# AT90PWM1 device description
Architecture: AVR8; Family: megaAVR
Registers are 8-bit, access not given, no defined reset value unless marked. A register's access mark holds for its fields unless they carry their own. Offsets are from the block's base; [hi:lo] are bit positions; {n}, {i} and the like mark numbered series; 'fields as' and 'values as' point back to an identical list.

## PSC2 — Power Stage Controller
Instances: PSC2 0x00
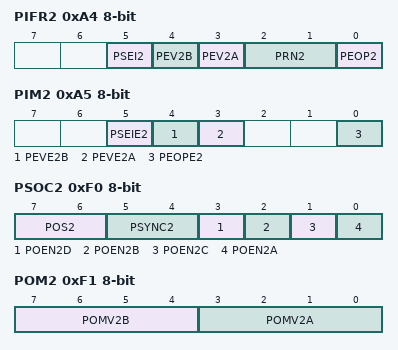
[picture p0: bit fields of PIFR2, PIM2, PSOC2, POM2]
0xA4 PIFR2 — PSC2 Interrupt Flag Register
  [5] PSEI2 — PSC 2 Synchro Error Interrupt
  [4] PEV2B — External Event B Interrupt
  [3] PEV2A — External Event A Interrupt
  [2:1] PRN2 — Ramp Number
    {v}={v+1} (v=0..3)
  [0] PEOP2 — End of PSC2 Interrupt
0xA5 PIM2 — PSC2 Interrupt Mask Register
  [5] PSEIE2 — PSC 2 Synchro Error Interrupt Enable
  [4] PEVE2B — External Event B Interrupt Enable
  [3] PEVE2A — External Event A Interrupt Enable
  [0] PEOPE2 — End of Cycle Interrupt Enable
0xF0 PSOC2 — PSC2 Synchro and Output Configuration
  [7:6] POS2 (bit 2 of the value upward) — PSC 2 Output 23 Select
  [5:4] PSYNC2 — Synchronization Out for ADC Selection
  [3] POEN2D — PSCOUT23 Output Enable
  [2] POEN2B — PSCOUT21 Output Enable
  [1] POEN2C — PSCOUT22 Output Enable
  [0] POEN2A — PSCOUT20 Output Enable
0xF1 POM2 — PSC 2 Output Matrix
  [7:4] POMV2B — Output Matrix Output B Ramps
  [3:0] POMV2A — Output Matrix Output A Ramps
0xF2 OCR2SA 16-bit bits used 11:0 — Output Compare SA Register
0xF4 OCR2RA 16-bit bits used 11:0 — Output Compare RA Register
0xF6 OCR2SB 16-bit bits used 11:0 — Output Compare SB Register
0xF8 OCR2RB 16-bit — Output Compare RB Register
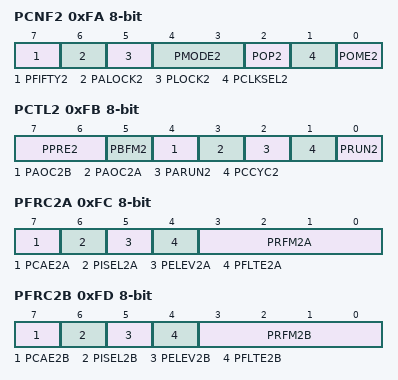
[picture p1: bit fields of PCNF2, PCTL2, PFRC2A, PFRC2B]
0xFA PCNF2 — PSC 2 Configuration Register
  [7] PFIFTY2 — PSC 2 Fifty
  [6] PALOCK2 — PSC 2 Autolock
  [5] PLOCK2 — PSC 2 Lock
  [4:3] PMODE2 — PSC 2 Mode
    0=One Ramp Mode; 1=Two Ramp Mode; 2=Four Ramp Mode; 3=Center Aligned Mode
  [2] POP2 — PSC 2 Output Polarity
  [1] PCLKSEL2 — PSC 2 Input Clock Select
  [0] POME2 — PSC 2 Output Matrix Enable
0xFB PCTL2 — PSC 2 Control Register
  [7:6] PPRE2 — PSC 2 Prescaler Selects
    0=No divider on PSC input clock; 1=Divide the PSC input clock by 4; 2=Divide the PSC input clock by 16; 3=Divide the PSC input clock by 64
  [5] PBFM2 — Balance Flank Width Modulation
  [4] PAOC2B — PSC 2 Asynchronous Output Control B
  [3] PAOC2A — PSC 2 Asynchronous Output Control A
  [2] PARUN2 — PSC2 Auto Run
  [1] PCCYC2 — PSC2 Complete Cycle
  [0] PRUN2 — PSC 2 Run
0xFC PFRC2A — PSC 2 Input B Control
  [7] PCAE2A — PSC 2 Capture Enable Input Part A
  [6] PISEL2A — PSC 2 Input Select for Part A
  [5] PELEV2A — PSC 2 Edge Level Selector on Input Part A
  [4] PFLTE2A — PSC 2 Filter Enable on Input Part A
  [3:0] PRFM2A — PSC 2 Retrigger and Fault Mode for Part A
    0=No action, PSC Input is ignored; 1=Stop signal, Jump to Opposite Dead-Time and Wait; 2=Stop signal, Execute Opposite Dead-Time and Wait; 3=Stop signal, Execute Opposite while Fault active; 4=Deactivate outputs without changing timing; 5=Stop signal and Insert Dead-Time; 6=Stop signal, Jump to Opposite Dead-Time and Wait; 7=Halt PSC and Wait for Software Action; 8=Edge Retrigger PSC; 9=Fixed Frequency Edge Retrigger PSC; 14=Fixed Frequency Edge Retrigger PSC and Disactivate Output
0xFD PFRC2B — PSC 2 Input B Control
  [7] PCAE2B — PSC 2 Capture Enable Input Part B
  [6] PISEL2B — PSC 2 Input Select for Part B
  [5] PELEV2B — PSC 2 Edge Level Selector on Input Part B
  [4] PFLTE2B — PSC 2 Filter Enable on Input Part B
  [3:0] PRFM2B — PSC 2 Retrigger and Fault Mode for Part B
    values as PFRC2A.PRFM2A
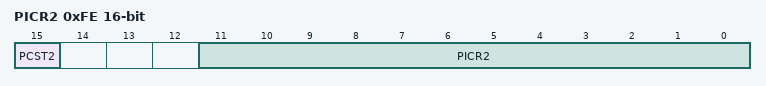
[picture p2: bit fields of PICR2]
0xFE PICR2 16-bit — PSC 2 Input Capture Register
  [15] PCST2 — PSC 2 Capture Software Trig bit
  [11:0] PICR2 — PSC 2 Input Capture Register

## PSC1 — Power Stage Controller
Instances: PSC1 0x00
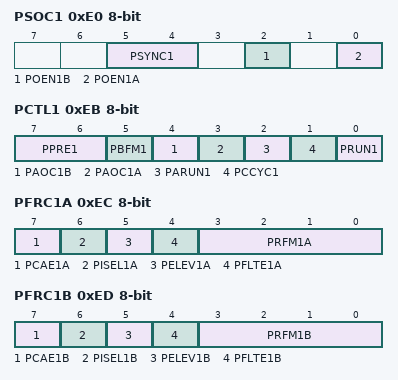
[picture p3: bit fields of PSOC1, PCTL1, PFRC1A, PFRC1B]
0xE0 PSOC1 — PSC1 Synchro and Output Configuration
  [5:4] PSYNC1 — Synchronization Out for ADC Selection
    0=Send signal on leading edge of PSCOUTn0; 1=Send signal on trailing edge of PSCOUTn0; 2=Send signal on leading edge of PSCOUTn1; 3=Send signal on trailing edge of PSCOUTn1
  [2] POEN1B — PSCOUT11 Output Enable
  [0] POEN1A — PSCOUT10 Output Enable
0xEB PCTL1 — PSC 1 Control Register
  [7:6] PPRE1 — PSC 1 Prescaler Selects
    0=No divider on PSC input clock; 1=Divide the PSC input clock by 4; 2=Divide the PSC input clock by 16; 3=Divide the PSC input clock by 64
  [5] PBFM1 — Balance Flank Width Modulation
  [4] PAOC1B — PSC 1 Asynchronous Output Control B
  [3] PAOC1A — PSC 1 Asynchronous Output Control A
  [2] PARUN1 — PSC1 Auto Run
  [1] PCCYC1 — PSC1 Complete Cycle
  [0] PRUN1 — PSC 1 Run
0xEC PFRC1A — PSC 1 Input B Control
  [7] PCAE1A — PSC 1 Capture Enable Input Part A
  [6] PISEL1A — PSC 1 Input Select for Part A
  [5] PELEV1A — PSC 1 Edge Level Selector on Input Part A
  [4] PFLTE1A — PSC 1 Filter Enable on Input Part A
  [3:0] PRFM1A — PSC 1 Retrigger and Fault Mode for Part A
    0=No action, PSC Input is ignored; 1=Stop signal, Jump to Opposite Dead-Time and Wait; 2=Stop signal, Execute Opposite Dead-Time and Wait; 3=Stop signal, Execute Opposite while Fault active; 4=Deactivate outputs without changing timing; 5=Stop signal and Insert Dead-Time; 6=Stop signal, Jump to Opposite Dead-Time and Wait; 7=Halt PSC and Wait for Software Action; 8=Edge Retrigger PSC; 9=Fixed Frequency Edge Retrigger PSC; 14=Fixed Frequency Edge Retrigger PSC and Disactivate Output
0xED PFRC1B — PSC 1 Input B Control
  [7] PCAE1B — PSC 1 Capture Enable Input Part B
  [6] PISEL1B — PSC 1 Input Select for Part B
  [5] PELEV1B — PSC 1 Edge Level Selector on Input Part B
  [4] PFLTE1B — PSC 1 Filter Enable on Input Part B
  [3:0] PRFM1B — PSC 1 Retrigger and Fault Mode for Part B
    values as PFRC1A.PRFM1A
0xEE PICR1 16-bit bits used 11:0 — PSC 1 Input Capture Register
